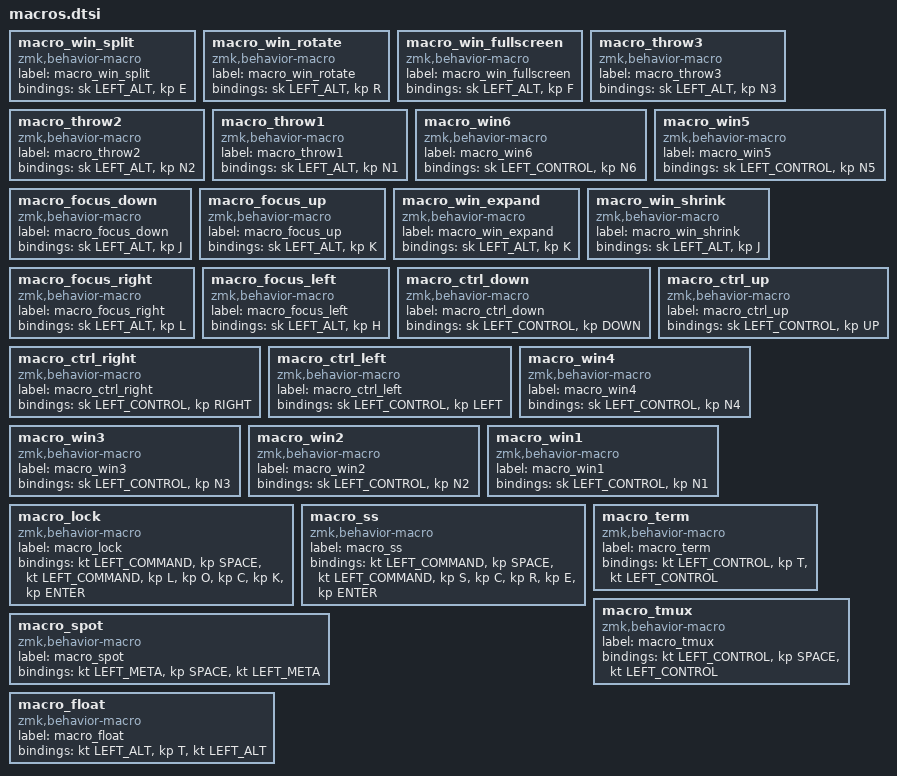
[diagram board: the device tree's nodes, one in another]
macro_win_split: macro_win_split{
compatible = "zmk,behavior-macro";
label = "macro_win_split";
#binding-cells = <0>;
bindings = <&sk LEFT_ALT>, <&kp E>;
};
macro_win_rotate: macro_win_rotate{
compatible = "zmk,behavior-macro";
label = "macro_win_rotate";
#binding-cells = <0>;
bindings = <&sk LEFT_ALT>, <&kp R>;
};
macro_win_fullscreen: macro_win_fullscreen{
compatible = "zmk,behavior-macro";
label = "macro_win_fullscreen";
#binding-cells = <0>;
bindings = <&sk LEFT_ALT>, <&kp F>;
};
macro_throw3: macro_throw3{
compatible = "zmk,behavior-macro";
label = "macro_throw3";
#binding-cells = <0>;
bindings = <&sk LEFT_ALT>, <&kp N3>;
};
macro_throw2: macro_throw2{
compatible = "zmk,behavior-macro";
label = "macro_throw2";
#binding-cells = <0>;
bindings = <&sk LEFT_ALT>, <&kp N2>;
};
macro_throw1: macro_throw1{
compatible = "zmk,behavior-macro";
label = "macro_throw1";
#binding-cells = <0>;
bindings = <&sk LEFT_ALT>, <&kp N1>;
};
macro_win6: macro_win6{
compatible = "zmk,behavior-macro";
label = "macro_win6";
#binding-cells = <0>;
bindings = <&sk LEFT_CONTROL>, <&kp N6>;
};
macro_win5: macro_win5{
compatible = "zmk,behavior-macro";
label = "macro_win5";
#binding-cells = <0>;
bindings = <&sk LEFT_CONTROL>, <&kp N5>;
};
macro_focus_down: macro_focus_down{
compatible = "zmk,behavior-macro";
label = "macro_focus_down";
#binding-cells = <0>;
bindings = <&sk LEFT_ALT>, <&kp J>;
};
macro_focus_up: macro_focus_up{
compatible = "zmk,behavior-macro";
label = "macro_focus_up";
#binding-cells = <0>;
bindings = <&sk LEFT_ALT>, <&kp K>;
};
macro_win_expand: macro_win_expand{
compatible = "zmk,behavior-macro";
label = "macro_win_expand";
#binding-cells = <0>;
bindings = <&sk LEFT_ALT>, <&kp K>;
};
macro_win_shrink: macro_win_shrink{
compatible = "zmk,behavior-macro";
label = "macro_win_shrink";
#binding-cells = <0>;
bindings = <&sk LEFT_ALT>, <&kp J>;
};
macro_focus_right: macro_focus_right{
compatible = "zmk,behavior-macro";
label = "macro_focus_right";
#binding-cells = <0>;
bindings = <&sk LEFT_ALT>, <&kp L>;
};
macro_focus_left: macro_focus_left{
compatible = "zmk,behavior-macro";
label = "macro_focus_left";
#binding-cells = <0>;
bindings = <&sk LEFT_ALT>, <&kp H>;
};
macro_ctrl_down: macro_ctrl_down{
compatible = "zmk,behavior-macro";
label = "macro_ctrl_down";
#binding-cells = <0>;
bindings = <&sk LEFT_CONTROL>, <&kp DOWN>;
};
macro_ctrl_up: macro_ctrl_up{
compatible = "zmk,behavior-macro";
label = "macro_ctrl_up";
#binding-cells = <0>;
bindings = <&sk LEFT_CONTROL>, <&kp UP>;
};
macro_ctrl_right: macro_ctrl_right{
compatible = "zmk,behavior-macro";
label = "macro_ctrl_right";
#binding-cells = <0>;
bindings = <&sk LEFT_CONTROL>, <&kp RIGHT>;
};
macro_ctrl_left: macro_ctrl_left{
compatible = "zmk,behavior-macro";
label = "macro_ctrl_left";
#binding-cells = <0>;
bindings = <&sk LEFT_CONTROL>, <&kp LEFT>;
};
macro_win4: macro_win4{
compatible = "zmk,behavior-macro";
label = "macro_win4";
#binding-cells = <0>;
bindings = <&sk LEFT_CONTROL>, <&kp N4>;
};
macro_win3: macro_win3{
compatible = "zmk,behavior-macro";
label = "macro_win3";
#binding-cells = <0>;
bindings = <&sk LEFT_CONTROL>, <&kp N3>;
};
macro_win2: macro_win2{
compatible = "zmk,behavior-macro";
label = "macro_win2";
#binding-cells = <0>;
bindings = <&sk LEFT_CONTROL>, <&kp N2>;
};
macro_win1: macro_win1{
compatible = "zmk,behavior-macro";
label = "macro_win1";
#binding-cells = <0>;
bindings = <&sk LEFT_CONTROL>, <&kp N1>;
};
macro_lock: macro_lock{
compatible = "zmk,behavior-macro";
label = "macro_lock";
#binding-cells = <0>;
bindings = <&kt LEFT_COMMAND>, <&kp SPACE>, <&kt LEFT_COMMAND>, <&kp L>, <&kp O>, <&kp C>, <&kp K>, <&kp ENTER>;
};
macro_ss: macro_ss{
compatible = "zmk,behavior-macro";
label = "macro_ss";
#binding-cells = <0>;
bindings = <&kt LEFT_COMMAND>, <&kp SPACE>, <&kt LEFT_COMMAND>, <&kp S>, <&kp C>, <&kp R>, <&kp E>, <&kp ENTER>;
};
macro_term: macro_term{
compatible = "zmk,behavior-macro";
label = "macro_term";
#binding-cells = <0>;
bindings = <&kt LEFT_CONTROL>, <&kp T>, <&kt LEFT_CONTROL>;
};
macro_spot: macro_spot{
compatible = "zmk,behavior-macro";
label = "macro_spot";
#binding-cells = <0>;
bindings = <&kt LEFT_META>, <&kp SPACE>, <&kt LEFT_META>;
};
macro_tmux: macro_tmux{
compatible = "zmk,behavior-macro";
label = "macro_tmux";
#binding-cells = <0>;
bindings = <&kt LEFT_CONTROL>, <&kp SPACE>, <&kt LEFT_CONTROL>;
};
macro_float: macro_float{
compatible = "zmk,behavior-macro";
label = "macro_float";
#binding-cells = <0>;
bindings = <&kt LEFT_ALT>, <&kp T>, <&kt LEFT_ALT>;
};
